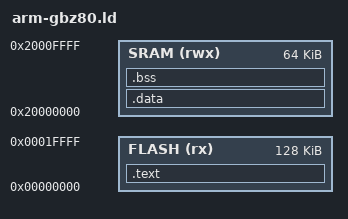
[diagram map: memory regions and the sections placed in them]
MEMORY
{
    FLASH (rx) : ORIGIN = 0x00000000, LENGTH = 128k
    SRAM (rwx) : ORIGIN = 0x20000000, LENGTH = 64k
}

SECTIONS
{
    .text :
    {
        _text = .;
        KEEP(*(.isr_vector))
        *(.text*)
        *(.rodata*)
        _etext = .;
    } > FLASH

    .data : AT(ADDR(.text) + SIZEOF(.text))
    {
        _data = .;
        *(vtable)
        *(.data*)
        _edata = .;
    } > SRAM

    .bss :
    {
        _bss = .;
        *(.bss*)
        *(COMMON)
        _ebss = .;
    } > SRAM
}
